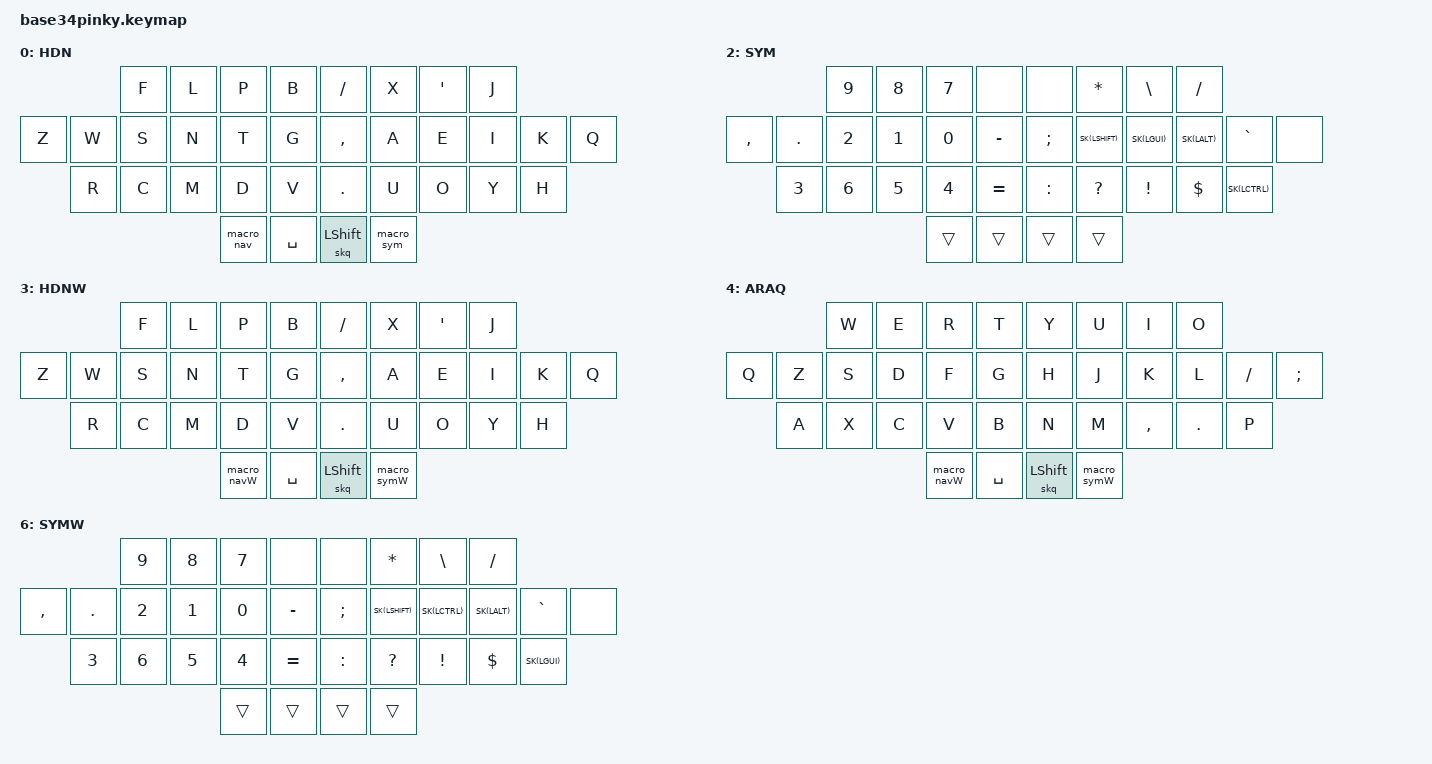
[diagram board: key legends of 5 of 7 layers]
/*
 * Copyright (c) 2020 The ZMK Contributors
 *
 * SPDX-License-Identifier: MIT
 */

#include <behaviors.dtsi>
#include <dt-bindings/zmk/keys.h>
#include <dt-bindings/zmk/bt.h>
#include <dt-bindings/zmk/outputs.h>

#define HDN 0
#define NAV 1
#define SYM 2
#define HDNW 3
#define ARAQ 4
#define NAVW 5
#define SYMW 6

#define SK(KEY) &nk KEY KEY
// Keep sticky keys active for a long time so they effectively do not time out
#define STICKY_KEY_TIMEOUT 60000

&sk {
  release-after-ms = <STICKY_KEY_TIMEOUT>;
};

&caps_word {
  continue-list = <UNDERSCORE MINUS BACKSPACE>;
};

/* KEY POSITIONS
  ╭───────────────────────╮          ╭───────────────────────╮
  │          0   1   2  3 │          │  4   5   6   7        │
  │  8   9  10  11  12 13 │          │ 14  15  16  17  18  19│
  │     20  21  22  23 24  ───╮ ╭────  25  26  27  28  29    │
  ╰─────────────────╮  30  31 │ │ 32  33 ╭───────────────────╯
                    ╰─────────╯ ╰────────╯           
*/

/ { 
  
                
  combos {
    #include "combos34.dtsi"
  };
  
  macros {
    #include "macros.dtsi"
  };

  behaviors {
    // Sticky key on tap, normal key on hold
    // Useful for modifier-clicking without the modifier remaining active
     nk: not_so_sticky_key {
       compatible = "zmk,behavior-hold-tap";
       label = "NOT_SO_STICKY_KEY";
       #binding-cells = <2>;
       tapping_term_ms = <200>;
       flavor = "tap-preferred";
       bindings = <&kp>, <&sk>;
     };

    skq: sticky_key_quick_release {
      compatible = "zmk,behavior-sticky-key";
      label = "STICKY_KEY_QUICK_RELEASE";
      #binding-cells = <1>;
      bindings = <&kp>;
      quick-release;
      release-after-ms = <STICKY_KEY_TIMEOUT>;
    };


  };
 
        keymap {
                compatible = "zmk,keymap";
                      
        handsdown {
            label = "HDN";
            bindings = <
// ╭─────────────┬─────────────┬─────────────┬─────────────┬─────────────╮   ╭─────────────┬─────────────┬─────────────┬─────────────┬─────────────╮
                      &kp F         &kp L         &kp P         &kp B             &kp SLASH     &kp X         &kp SQT       &kp J
&kp Z   &kp W         &kp S         &kp N         &kp T         &kp G             &kp COMMA     &kp A         &kp E         &kp I         &kp K  &kp Q
        &kp R         &kp C         &kp M         &kp D         &kp V             &kp DOT       &kp U         &kp O         &kp Y         &kp H
// ╰─────────────┴─────────────┴─────────────┼─────────────┼─────────────┤   ├─────────────┼─────────────┼─────────────┴─────────────┴─────────────╯
                                               &macro_nav    &kp SPACE         &skq LSHIFT    &macro_sym
//                                           ╰─────────────┴─────────────╯   ╰─────────────┴─────────────╯
            >;
        };

        navitation {
            label = "NAV";
            bindings = <
// ╭─────────────┬─────────────┬─────────────┬─────────────┬─────────────╮   ╭─────────────┬─────────────┬─────────────┬─────────────┬─────────────╮
                    &kp ENTER     &kp BACKSPACE  &kp TAB       &kp LA(BACKSPACE)  &kp LA(BACKSPACE) &none         &kp UP        &kp LG(Q)     
&none   &none       SK(LALT)      SK(LGUI)       SK(LSHIFT)    &kp DELETE         &none             &kp LEFT      &kp DOWN      &kp RIGHT     &none &none
        SK(LCTL)    &kp LG(X)     &kp LG(C)      &kp LG(V)     &kp LG(A)          &kp LG(A)         &kp ENTER     &kp BACKSPACE &kp TAB       &kp LG(LC(LA(LS(P))))
// ╰─────────────┴─────────────┴─────────────┼─────────────┼─────────────┤   ├─────────────┼─────────────┼─────────────┴─────────────┴─────────────╯
                                               &trans         &trans            &trans        &trans
//                                           ╰─────────────┴─────────────╯   ╰─────────────┴─────────────╯
            >;
        };
        symbols {
            label = "SYM";
            bindings = <
// ╭─────────────┬─────────────┬─────────────┬─────────────┬─────────────╮   ╭─────────────┬─────────────┬─────────────┬─────────────┬─────────────╮
                      &kp N9       &kp N8         &kp N7         &none             &none        &kp ASTRK     &kp BSLH     &kp SLASH     
&kp COMMA  &kp DOT    &kp N2       &kp N1         &kp N0         &kp MINUS         &kp SEMI     SK(LSHIFT)    SK(LGUI)     SK(LALT)      &kp GRAVE &none
           &kp N3     &kp N6       &kp N5         &kp N4         &kp EQUAL         &kp COLON    &kp QMARK     &kp EXCL     &kp DLLR      SK(LCTRL) 
// ╰─────────────┴─────────────┴─────────────┼─────────────┼─────────────┤   ├─────────────┼─────────────┼─────────────┴─────────────┴─────────────╯
                                               &trans         &trans            &trans       &trans
//                                           ╰─────────────┴─────────────╯   ╰─────────────┴─────────────╯
            >;
        };

        handsdown_windows {
            label = "HDNW";
            bindings = <
// ╭─────────────┬─────────────┬─────────────┬─────────────┬─────────────╮   ╭─────────────┬─────────────┬─────────────┬─────────────┬─────────────╮
                      &kp F         &kp L         &kp P         &kp B             &kp SLASH     &kp X         &kp SQT       &kp J
&kp Z   &kp W         &kp S         &kp N         &kp T         &kp G             &kp COMMA     &kp A         &kp E         &kp I         &kp K  &kp Q
        &kp R         &kp C         &kp M         &kp D         &kp V             &kp DOT       &kp U         &kp O         &kp Y         &kp H
// ╰─────────────┴─────────────┴─────────────┼─────────────┼─────────────┤   ├─────────────┼─────────────┼─────────────┴─────────────┴─────────────╯
                                               &macro_navW   &kp SPACE         &skq LSHIFT    &macro_symW
//                                           ╰─────────────┴─────────────╯   ╰─────────────┴─────────────╯
            >;
        };

        arabic_qwerty {
            label = "ARAQ";
            bindings = <
// ╭─────────────┬─────────────┬─────────────┬─────────────┬─────────────╮   ╭─────────────┬─────────────┬─────────────┬─────────────┬─────────────╮
                     &kp W         &kp E         &kp R         &kp T             &kp Y         &kp U         &kp I         &kp O        
&kp Q  &kp Z         &kp S         &kp D         &kp F         &kp G             &kp H         &kp J         &kp K         &kp L         &kp SLASH &kp SEMICOLON
       &kp A         &kp X         &kp C         &kp V         &kp B             &kp N         &kp M         &kp COMMA     &kp DOT       &kp P 
// ╰─────────────┴─────────────┴─────────────┼─────────────┼─────────────┤   ├─────────────┼─────────────┼─────────────┴─────────────┴─────────────╯
                                               &macro_navW   &kp SPACE         &skq LSHIFT    &macro_symW
//                                           ╰─────────────┴─────────────╯   ╰─────────────┴─────────────╯
            >;
        };

        navigation_windows {
            label = "NAVW";
            bindings = <
// ╭─────────────┬─────────────┬─────────────┬─────────────┬─────────────╮   ╭─────────────┬─────────────┬─────────────┬─────────────┬─────────────╮
                     &kp ENTER     &kp BACKSPACE  &kp TAB      &kp LC(BACKSPACE)   &kp LC(BACKSPACE)  &none         &kp UP        &kp LA(F4)    
 &none  &none        SK(LALT)      SK(LCTRL)      SK(LSHIFT)   &kp DELETE          &none              &kp LEFT      &kp DOWN      &kp RIGHT     &none  &none
     SK(LGUI)        &kp LC(X)     &kp LC(C)      &kp LC(V)    &kp LC(A)           &kp LC(A)          &kp ENTER     &kp BACKSPACE &kp TAB       &kp LC(LA(LS(P)))
// ╰─────────────┴─────────────┴─────────────┼─────────────┼─────────────┤   ├─────────────┼─────────────┼─────────────┴─────────────┴─────────────╯
                                               &trans          &trans            &trans        &trans
//                                           ╰─────────────┴─────────────╯   ╰─────────────┴─────────────╯
            >;
        };

        symbols_windows {
            label = "SYMW";
            bindings = <
// ╭─────────────┬─────────────┬─────────────┬─────────────┬─────────────╮   ╭─────────────┬─────────────┬─────────────┬─────────────┬─────────────╮
                        &kp N9     &kp N8       &kp N7       &none             &none         &kp ASTRK     &kp BSLH     &kp SLASH     
&kp COMMA   &kp DOT     &kp N2     &kp N1       &kp N0       &kp MINUS         &kp SEMI      SK(LSHIFT)    SK(LCTRL)     SK(LALT)     &kp GRAVE &none 
            &kp N3      &kp N6     &kp N5       &kp N4       &kp EQUAL         &kp COLON     &kp QMARK     &kp EXCL     &kp DLLR      SK(LGUI) 
// ╰─────────────┴─────────────┴─────────────┼─────────────┼─────────────┤   ├─────────────┼─────────────┼─────────────┴─────────────┴─────────────╯
                                               &trans        &trans            &trans        &trans
//                                           ╰─────────────┴─────────────╯   ╰─────────────┴─────────────╯
            >;
        };
};

};
